AUTOSAR XML (schema 4-0-3)
standard types defined: Boolean, UInt16
package /AUTOSAR_Platform/DataConstrs
  range DC_Boolean: raw 0..1
  range DC_UInt16: raw 0..65535
package /PATAC/MSM/ComponentTypes
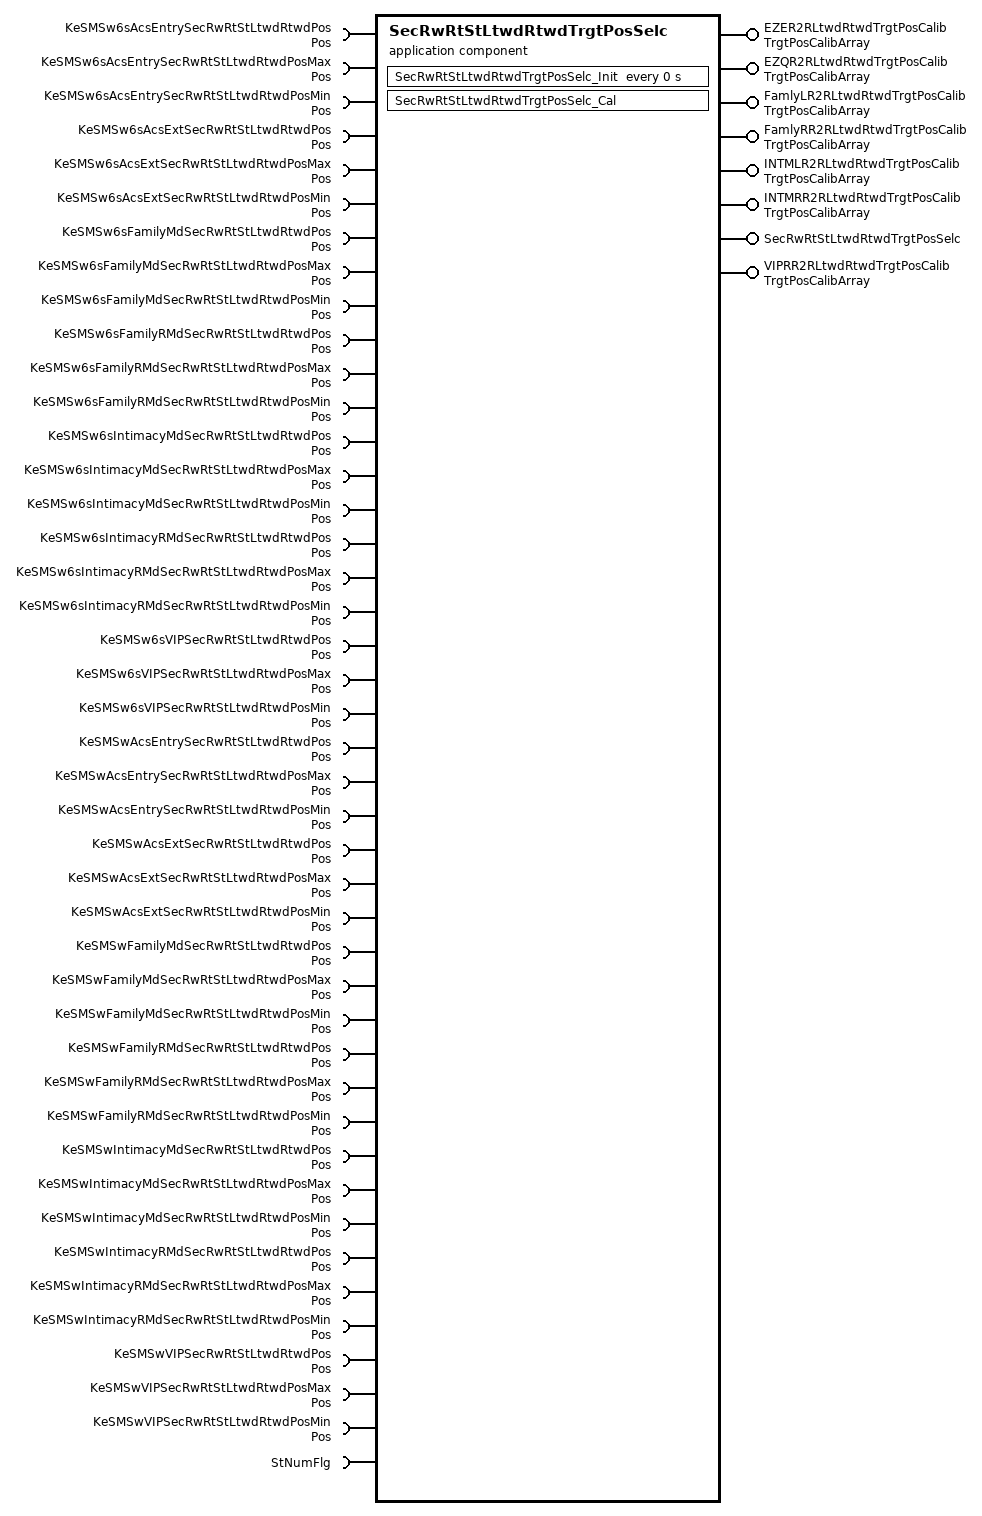
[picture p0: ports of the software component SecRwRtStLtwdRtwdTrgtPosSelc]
  application sw component type SecRwRtStLtwdRtwdTrgtPosSelc
    8 x provide port:
      EZER2RLtwdRtwdTrgtPosCalib: nonqueued-sender-com-spec{data-element=TrgtPosArray, init-value=[4095, 4095, 4095]}, provided-interface=TrgtPosCalibArray
      EZQR2RLtwdRtwdTrgtPosCalib: nonqueued-sender-com-spec{data-element=TrgtPosArray, init-value=[4095, 4095, 4095]}, provided-interface=TrgtPosCalibArray
      FamlyLR2RLtwdRtwdTrgtPosCalib: nonqueued-sender-com-spec{data-element=TrgtPosArray, init-value=[4095, 4095, 4095]}, provided-interface=TrgtPosCalibArray
      FamlyRR2RLtwdRtwdTrgtPosCalib: nonqueued-sender-com-spec{data-element=TrgtPosArray, init-value=[4095, 4095, 4095]}, provided-interface=TrgtPosCalibArray
      INTMLR2RLtwdRtwdTrgtPosCalib: nonqueued-sender-com-spec{data-element=TrgtPosArray, init-value=[4095, 4095, 4095]}, provided-interface=TrgtPosCalibArray
      INTMRR2RLtwdRtwdTrgtPosCalib: nonqueued-sender-com-spec{data-element=TrgtPosArray, init-value=[4095, 4095, 4095]}, provided-interface=TrgtPosCalibArray
      SecRwRtStLtwdRtwdTrgtPosSelc: server-com-spec{operation=Cal, queue-length=1}, provided-interface=SecRwRtStLtwdRtwdTrgtPosSelc
      VIPRR2RLtwdRtwdTrgtPosCalib: nonqueued-sender-com-spec{data-element=TrgtPosArray, init-value=[4095, 4095, 4095]}, provided-interface=TrgtPosCalibArray
    43 x require port:
      KeSMSw6sAcsEntrySecRwRtStLtwdRtwdPos: parameter-require-com-spec{init-value=4000, parameter=Val}, required-interface=Pos
      KeSMSw6sAcsEntrySecRwRtStLtwdRtwdPosMax: parameter-require-com-spec{init-value=4000, parameter=Val}, required-interface=Pos
      KeSMSw6sAcsEntrySecRwRtStLtwdRtwdPosMin: parameter-require-com-spec{init-value=4000, parameter=Val}, required-interface=Pos
      KeSMSw6sAcsExtSecRwRtStLtwdRtwdPos: parameter-require-com-spec{init-value=4000, parameter=Val}, required-interface=Pos
      KeSMSw6sAcsExtSecRwRtStLtwdRtwdPosMax: parameter-require-com-spec{init-value=4000, parameter=Val}, required-interface=Pos
      KeSMSw6sAcsExtSecRwRtStLtwdRtwdPosMin: parameter-require-com-spec{init-value=4000, parameter=Val}, required-interface=Pos
      KeSMSw6sFamilyMdSecRwRtStLtwdRtwdPos: parameter-require-com-spec{init-value=0, parameter=Val}, required-interface=Pos
      KeSMSw6sFamilyMdSecRwRtStLtwdRtwdPosMax: parameter-require-com-spec{init-value=0, parameter=Val}, required-interface=Pos
      KeSMSw6sFamilyMdSecRwRtStLtwdRtwdPosMin: parameter-require-com-spec{init-value=0, parameter=Val}, required-interface=Pos
      KeSMSw6sFamilyRMdSecRwRtStLtwdRtwdPos: parameter-require-com-spec{init-value=0, parameter=Val}, required-interface=Pos
      KeSMSw6sFamilyRMdSecRwRtStLtwdRtwdPosMax: parameter-require-com-spec{init-value=0, parameter=Val}, required-interface=Pos
      KeSMSw6sFamilyRMdSecRwRtStLtwdRtwdPosMin: parameter-require-com-spec{init-value=0, parameter=Val}, required-interface=Pos
      KeSMSw6sIntimacyMdSecRwRtStLtwdRtwdPos: parameter-require-com-spec{init-value=0, parameter=Val}, required-interface=Pos
      KeSMSw6sIntimacyMdSecRwRtStLtwdRtwdPosMax: parameter-require-com-spec{init-value=0, parameter=Val}, required-interface=Pos
      KeSMSw6sIntimacyMdSecRwRtStLtwdRtwdPosMin: parameter-require-com-spec{init-value=0, parameter=Val}, required-interface=Pos
      KeSMSw6sIntimacyRMdSecRwRtStLtwdRtwdPos: parameter-require-com-spec{init-value=0, parameter=Val}, required-interface=Pos
      KeSMSw6sIntimacyRMdSecRwRtStLtwdRtwdPosMax: parameter-require-com-spec{init-value=0, parameter=Val}, required-interface=Pos
      KeSMSw6sIntimacyRMdSecRwRtStLtwdRtwdPosMin: parameter-require-com-spec{init-value=0, parameter=Val}, required-interface=Pos
      KeSMSw6sVIPSecRwRtStLtwdRtwdPos: parameter-require-com-spec{init-value=0, parameter=Val}, required-interface=Pos
      KeSMSw6sVIPSecRwRtStLtwdRtwdPosMax: parameter-require-com-spec{init-value=40, parameter=Val}, required-interface=Pos
      KeSMSw6sVIPSecRwRtStLtwdRtwdPosMin: parameter-require-com-spec{init-value=0, parameter=Val}, required-interface=Pos
      KeSMSwAcsEntrySecRwRtStLtwdRtwdPos: parameter-require-com-spec{init-value=4000, parameter=Val}, required-interface=Pos
      KeSMSwAcsEntrySecRwRtStLtwdRtwdPosMax: parameter-require-com-spec{init-value=4000, parameter=Val}, required-interface=Pos
      KeSMSwAcsEntrySecRwRtStLtwdRtwdPosMin: parameter-require-com-spec{init-value=4000, parameter=Val}, required-interface=Pos
      KeSMSwAcsExtSecRwRtStLtwdRtwdPos: parameter-require-com-spec{init-value=4000, parameter=Val}, required-interface=Pos
      KeSMSwAcsExtSecRwRtStLtwdRtwdPosMax: parameter-require-com-spec{init-value=4000, parameter=Val}, required-interface=Pos
      KeSMSwAcsExtSecRwRtStLtwdRtwdPosMin: parameter-require-com-spec{init-value=4000, parameter=Val}, required-interface=Pos
      KeSMSwFamilyMdSecRwRtStLtwdRtwdPos: parameter-require-com-spec{init-value=0, parameter=Val}, required-interface=Pos
      KeSMSwFamilyMdSecRwRtStLtwdRtwdPosMax: parameter-require-com-spec{init-value=0, parameter=Val}, required-interface=Pos
      KeSMSwFamilyMdSecRwRtStLtwdRtwdPosMin: parameter-require-com-spec{init-value=0, parameter=Val}, required-interface=Pos
      KeSMSwFamilyRMdSecRwRtStLtwdRtwdPos: parameter-require-com-spec{init-value=0, parameter=Val}, required-interface=Pos
      KeSMSwFamilyRMdSecRwRtStLtwdRtwdPosMax: parameter-require-com-spec{init-value=0, parameter=Val}, required-interface=Pos
      KeSMSwFamilyRMdSecRwRtStLtwdRtwdPosMin: parameter-require-com-spec{init-value=0, parameter=Val}, required-interface=Pos
      KeSMSwIntimacyMdSecRwRtStLtwdRtwdPos: parameter-require-com-spec{init-value=0, parameter=Val}, required-interface=Pos
      KeSMSwIntimacyMdSecRwRtStLtwdRtwdPosMax: parameter-require-com-spec{init-value=0, parameter=Val}, required-interface=Pos
      KeSMSwIntimacyMdSecRwRtStLtwdRtwdPosMin: parameter-require-com-spec{init-value=0, parameter=Val}, required-interface=Pos
      KeSMSwIntimacyRMdSecRwRtStLtwdRtwdPos: parameter-require-com-spec{init-value=0, parameter=Val}, required-interface=Pos
      KeSMSwIntimacyRMdSecRwRtStLtwdRtwdPosMax: parameter-require-com-spec{init-value=0, parameter=Val}, required-interface=Pos
      KeSMSwIntimacyRMdSecRwRtStLtwdRtwdPosMin: parameter-require-com-spec{init-value=0, parameter=Val}, required-interface=Pos
      KeSMSwVIPSecRwRtStLtwdRtwdPos: parameter-require-com-spec{init-value=0, parameter=Val}, required-interface=Pos
      KeSMSwVIPSecRwRtStLtwdRtwdPosMax: parameter-require-com-spec{init-value=40, parameter=Val}, required-interface=Pos
      KeSMSwVIPSecRwRtStLtwdRtwdPosMin: parameter-require-com-spec{init-value=0, parameter=Val}, required-interface=Pos
      StNumFlg: required-interface=StNumFlg
        required-com-specs:
          data-element=Is4s, filter=data-filter-type=ALWAYS, init-value=0
          data-element=Is6s, filter=data-filter-type=ALWAYS, init-value=0
          data-element=Is6s7s, filter=data-filter-type=ALWAYS, init-value=0
          data-element=Is7s, filter=data-filter-type=ALWAYS, init-value=0
    behavior SecRwRtStLtwdRtwdTrgtPosSelc_InternalBehavior
      operation invoked event OIT_SecRwRtStLtwdRtwdTrgtPosSelc_Cal_SecRwRtStLtwdRtwdTrgtPosSelc_Cal: start-on-event=SecRwRtStLtwdRtwdTrgtPosSelc_Cal, operation=SecRwRtStLtwdRtwdTrgtPosSelc.Cal
      timing event SecRwRtStLtwdRtwdTrgtPosSelc_InitEvent: start-on-event=SecRwRtStLtwdRtwdTrgtPosSelc_Init, period=0
      runnable SecRwRtStLtwdRtwdTrgtPosSelc_Cal
        data-receive-point-by-arguments:
          4 x access:
            REC_StNumFlg_Is4s: accessed-variable=StNumFlg.Is4s
            REC_StNumFlg_Is6s: accessed-variable=StNumFlg.Is6s
            REC_StNumFlg_Is6s7s: accessed-variable=StNumFlg.Is6s7s
            REC_StNumFlg_Is7s: accessed-variable=StNumFlg.Is7s
        data-send-points:
          7 x access:
            SEND_EZER2RLtwdRtwdTrgtPosCalib_TrgtPosArray: accessed-variable=EZER2RLtwdRtwdTrgtPosCalib.TrgtPosArray
            SEND_EZQR2RLtwdRtwdTrgtPosCalib_TrgtPosArray: accessed-variable=EZQR2RLtwdRtwdTrgtPosCalib.TrgtPosArray
            SEND_FamlyLR2RLtwdRtwdTrgtPosCalib_TrgtPosArray: accessed-variable=FamlyLR2RLtwdRtwdTrgtPosCalib.TrgtPosArray
            SEND_FamlyRR2RLtwdRtwdTrgtPosCalib_TrgtPosArray: accessed-variable=FamlyRR2RLtwdRtwdTrgtPosCalib.TrgtPosArray
            SEND_INTMLR2RLtwdRtwdTrgtPosCalib_TrgtPosArray: accessed-variable=INTMLR2RLtwdRtwdTrgtPosCalib.TrgtPosArray
            SEND_INTMRR2RLtwdRtwdTrgtPosCalib_TrgtPosArray: accessed-variable=INTMRR2RLtwdRtwdTrgtPosCalib.TrgtPosArray
            SEND_VIPRR2RLtwdRtwdTrgtPosCalib_TrgtPosArray: accessed-variable=VIPRR2RLtwdRtwdTrgtPosCalib.TrgtPosArray
        42 x parameter access:
          PA_KeSMSw6sAcsEntrySecRwRtStLtwdRtwdPos_Val: accessed-parameter=KeSMSw6sAcsEntrySecRwRtStLtwdRtwdPos.Val
          PA_KeSMSw6sAcsEntrySecRwRtStLtwdRtwdPosMax_Val: accessed-parameter=KeSMSw6sAcsEntrySecRwRtStLtwdRtwdPosMax.Val
          PA_KeSMSw6sAcsEntrySecRwRtStLtwdRtwdPosMin_Val: accessed-parameter=KeSMSw6sAcsEntrySecRwRtStLtwdRtwdPosMin.Val
          PA_KeSMSw6sAcsExtSecRwRtStLtwdRtwdPos_Val: accessed-parameter=KeSMSw6sAcsExtSecRwRtStLtwdRtwdPos.Val
          PA_KeSMSw6sAcsExtSecRwRtStLtwdRtwdPosMax_Val: accessed-parameter=KeSMSw6sAcsExtSecRwRtStLtwdRtwdPosMax.Val
          PA_KeSMSw6sAcsExtSecRwRtStLtwdRtwdPosMin_Val: accessed-parameter=KeSMSw6sAcsExtSecRwRtStLtwdRtwdPosMin.Val
          PA_KeSMSw6sFamilyMdSecRwRtStLtwdRtwdPos_Val: accessed-parameter=KeSMSw6sFamilyMdSecRwRtStLtwdRtwdPos.Val
          PA_KeSMSw6sFamilyMdSecRwRtStLtwdRtwdPosMax_Val: accessed-parameter=KeSMSw6sFamilyMdSecRwRtStLtwdRtwdPosMax.Val
          PA_KeSMSw6sFamilyMdSecRwRtStLtwdRtwdPosMin_Val: accessed-parameter=KeSMSw6sFamilyMdSecRwRtStLtwdRtwdPosMin.Val
          PA_KeSMSw6sFamilyRMdSecRwRtStLtwdRtwdPos_Val: accessed-parameter=KeSMSw6sFamilyRMdSecRwRtStLtwdRtwdPos.Val
          PA_KeSMSw6sFamilyRMdSecRwRtStLtwdRtwdPosMax_Val: accessed-parameter=KeSMSw6sFamilyRMdSecRwRtStLtwdRtwdPosMax.Val
          PA_KeSMSw6sFamilyRMdSecRwRtStLtwdRtwdPosMin_Val: accessed-parameter=KeSMSw6sFamilyRMdSecRwRtStLtwdRtwdPosMin.Val
          PA_KeSMSw6sIntimacyMdSecRwRtStLtwdRtwdPos_Val: accessed-parameter=KeSMSw6sIntimacyMdSecRwRtStLtwdRtwdPos.Val
          PA_KeSMSw6sIntimacyMdSecRwRtStLtwdRtwdPosMax_Val: accessed-parameter=KeSMSw6sIntimacyMdSecRwRtStLtwdRtwdPosMax.Val
          PA_KeSMSw6sIntimacyMdSecRwRtStLtwdRtwdPosMin_Val: accessed-parameter=KeSMSw6sIntimacyMdSecRwRtStLtwdRtwdPosMin.Val
          PA_KeSMSw6sIntimacyRMdSecRwRtStLtwdRtwdPos_Val: accessed-parameter=KeSMSw6sIntimacyRMdSecRwRtStLtwdRtwdPos.Val
          PA_KeSMSw6sIntimacyRMdSecRwRtStLtwdRtwdPosMax_Val: accessed-parameter=KeSMSw6sIntimacyRMdSecRwRtStLtwdRtwdPosMax.Val
          PA_KeSMSw6sIntimacyRMdSecRwRtStLtwdRtwdPosMin_Val: accessed-parameter=KeSMSw6sIntimacyRMdSecRwRtStLtwdRtwdPosMin.Val
          PA_KeSMSw6sVIPSecRwRtStLtwdRtwdPos_Val: accessed-parameter=KeSMSw6sVIPSecRwRtStLtwdRtwdPos.Val
          PA_KeSMSw6sVIPSecRwRtStLtwdRtwdPosMax_Val: accessed-parameter=KeSMSw6sVIPSecRwRtStLtwdRtwdPosMax.Val
          PA_KeSMSw6sVIPSecRwRtStLtwdRtwdPosMin_Val: accessed-parameter=KeSMSw6sVIPSecRwRtStLtwdRtwdPosMin.Val
          PA_KeSMSwAcsEntrySecRwRtStLtwdRtwdPos_Val: accessed-parameter=KeSMSwAcsEntrySecRwRtStLtwdRtwdPos.Val
          PA_KeSMSwAcsEntrySecRwRtStLtwdRtwdPosMax_Val: accessed-parameter=KeSMSwAcsEntrySecRwRtStLtwdRtwdPosMax.Val
          PA_KeSMSwAcsEntrySecRwRtStLtwdRtwdPosMin_Val: accessed-parameter=KeSMSwAcsEntrySecRwRtStLtwdRtwdPosMin.Val
          PA_KeSMSwAcsExtSecRwRtStLtwdRtwdPos_Val: accessed-parameter=KeSMSwAcsExtSecRwRtStLtwdRtwdPos.Val
          PA_KeSMSwAcsExtSecRwRtStLtwdRtwdPosMax_Val: accessed-parameter=KeSMSwAcsExtSecRwRtStLtwdRtwdPosMax.Val
          PA_KeSMSwAcsExtSecRwRtStLtwdRtwdPosMin_Val: accessed-parameter=KeSMSwAcsExtSecRwRtStLtwdRtwdPosMin.Val
          PA_KeSMSwFamilyMdSecRwRtStLtwdRtwdPos_Val: accessed-parameter=KeSMSwFamilyMdSecRwRtStLtwdRtwdPos.Val
          PA_KeSMSwFamilyMdSecRwRtStLtwdRtwdPosMax_Val: accessed-parameter=KeSMSwFamilyMdSecRwRtStLtwdRtwdPosMax.Val
          PA_KeSMSwFamilyMdSecRwRtStLtwdRtwdPosMin_Val: accessed-parameter=KeSMSwFamilyMdSecRwRtStLtwdRtwdPosMin.Val
          PA_KeSMSwFamilyRMdSecRwRtStLtwdRtwdPos_Val: accessed-parameter=KeSMSwFamilyRMdSecRwRtStLtwdRtwdPos.Val
          PA_KeSMSwFamilyRMdSecRwRtStLtwdRtwdPosMax_Val: accessed-parameter=KeSMSwFamilyRMdSecRwRtStLtwdRtwdPosMax.Val
          PA_KeSMSwFamilyRMdSecRwRtStLtwdRtwdPosMin_Val: accessed-parameter=KeSMSwFamilyRMdSecRwRtStLtwdRtwdPosMin.Val
          PA_KeSMSwIntimacyMdSecRwRtStLtwdRtwdPos_Val: accessed-parameter=KeSMSwIntimacyMdSecRwRtStLtwdRtwdPos.Val
          PA_KeSMSwIntimacyMdSecRwRtStLtwdRtwdPosMax_Val: accessed-parameter=KeSMSwIntimacyMdSecRwRtStLtwdRtwdPosMax.Val
          PA_KeSMSwIntimacyMdSecRwRtStLtwdRtwdPosMin_Val: accessed-parameter=KeSMSwIntimacyMdSecRwRtStLtwdRtwdPosMin.Val
          PA_KeSMSwIntimacyRMdSecRwRtStLtwdRtwdPos_Val: accessed-parameter=KeSMSwIntimacyRMdSecRwRtStLtwdRtwdPos.Val
          PA_KeSMSwIntimacyRMdSecRwRtStLtwdRtwdPosMax_Val: accessed-parameter=KeSMSwIntimacyRMdSecRwRtStLtwdRtwdPosMax.Val
          PA_KeSMSwIntimacyRMdSecRwRtStLtwdRtwdPosMin_Val: accessed-parameter=KeSMSwIntimacyRMdSecRwRtStLtwdRtwdPosMin.Val
          PA_KeSMSwVIPSecRwRtStLtwdRtwdPos_Val: accessed-parameter=KeSMSwVIPSecRwRtStLtwdRtwdPos.Val
          PA_KeSMSwVIPSecRwRtStLtwdRtwdPosMax_Val: accessed-parameter=KeSMSwVIPSecRwRtStLtwdRtwdPosMax.Val
          PA_KeSMSwVIPSecRwRtStLtwdRtwdPosMin_Val: accessed-parameter=KeSMSwVIPSecRwRtStLtwdRtwdPosMin.Val
      runnable SecRwRtStLtwdRtwdTrgtPosSelc_Init
        42 x parameter access:
          PA_KeSMSw6sAcsEntrySecRwRtStLtwdRtwdPos_Val: accessed-parameter=KeSMSw6sAcsEntrySecRwRtStLtwdRtwdPos.Val
          PA_KeSMSw6sAcsEntrySecRwRtStLtwdRtwdPosMax_Val: accessed-parameter=KeSMSw6sAcsEntrySecRwRtStLtwdRtwdPosMax.Val
          PA_KeSMSw6sAcsEntrySecRwRtStLtwdRtwdPosMin_Val: accessed-parameter=KeSMSw6sAcsEntrySecRwRtStLtwdRtwdPosMin.Val
          PA_KeSMSw6sAcsExtSecRwRtStLtwdRtwdPos_Val: accessed-parameter=KeSMSw6sAcsExtSecRwRtStLtwdRtwdPos.Val
          PA_KeSMSw6sAcsExtSecRwRtStLtwdRtwdPosMax_Val: accessed-parameter=KeSMSw6sAcsExtSecRwRtStLtwdRtwdPosMax.Val
          PA_KeSMSw6sAcsExtSecRwRtStLtwdRtwdPosMin_Val: accessed-parameter=KeSMSw6sAcsExtSecRwRtStLtwdRtwdPosMin.Val
          PA_KeSMSw6sFamilyMdSecRwRtStLtwdRtwdPos_Val: accessed-parameter=KeSMSw6sFamilyMdSecRwRtStLtwdRtwdPos.Val
          PA_KeSMSw6sFamilyMdSecRwRtStLtwdRtwdPosMax_Val: accessed-parameter=KeSMSw6sFamilyMdSecRwRtStLtwdRtwdPosMax.Val
          PA_KeSMSw6sFamilyMdSecRwRtStLtwdRtwdPosMin_Val: accessed-parameter=KeSMSw6sFamilyMdSecRwRtStLtwdRtwdPosMin.Val
          PA_KeSMSw6sFamilyRMdSecRwRtStLtwdRtwdPos_Val: accessed-parameter=KeSMSw6sFamilyRMdSecRwRtStLtwdRtwdPos.Val
          PA_KeSMSw6sFamilyRMdSecRwRtStLtwdRtwdPosMax_Val: accessed-parameter=KeSMSw6sFamilyRMdSecRwRtStLtwdRtwdPosMax.Val
          PA_KeSMSw6sFamilyRMdSecRwRtStLtwdRtwdPosMin_Val: accessed-parameter=KeSMSw6sFamilyRMdSecRwRtStLtwdRtwdPosMin.Val
          PA_KeSMSw6sIntimacyMdSecRwRtStLtwdRtwdPos_Val: accessed-parameter=KeSMSw6sIntimacyMdSecRwRtStLtwdRtwdPos.Val
          PA_KeSMSw6sIntimacyMdSecRwRtStLtwdRtwdPosMax_Val: accessed-parameter=KeSMSw6sIntimacyMdSecRwRtStLtwdRtwdPosMax.Val
          PA_KeSMSw6sIntimacyMdSecRwRtStLtwdRtwdPosMin_Val: accessed-parameter=KeSMSw6sIntimacyMdSecRwRtStLtwdRtwdPosMin.Val
          PA_KeSMSw6sIntimacyRMdSecRwRtStLtwdRtwdPos_Val: accessed-parameter=KeSMSw6sIntimacyRMdSecRwRtStLtwdRtwdPos.Val
          PA_KeSMSw6sIntimacyRMdSecRwRtStLtwdRtwdPosMax_Val: accessed-parameter=KeSMSw6sIntimacyRMdSecRwRtStLtwdRtwdPosMax.Val
          PA_KeSMSw6sIntimacyRMdSecRwRtStLtwdRtwdPosMin_Val: accessed-parameter=KeSMSw6sIntimacyRMdSecRwRtStLtwdRtwdPosMin.Val
          PA_KeSMSw6sVIPSecRwRtStLtwdRtwdPos_Val: accessed-parameter=KeSMSw6sVIPSecRwRtStLtwdRtwdPos.Val
          PA_KeSMSw6sVIPSecRwRtStLtwdRtwdPosMax_Val: accessed-parameter=KeSMSw6sVIPSecRwRtStLtwdRtwdPosMax.Val
          PA_KeSMSw6sVIPSecRwRtStLtwdRtwdPosMin_Val: accessed-parameter=KeSMSw6sVIPSecRwRtStLtwdRtwdPosMin.Val
          PA_KeSMSwAcsEntrySecRwRtStLtwdRtwdPos_Val: accessed-parameter=KeSMSwAcsEntrySecRwRtStLtwdRtwdPos.Val
          PA_KeSMSwAcsEntrySecRwRtStLtwdRtwdPosMax_Val: accessed-parameter=KeSMSwAcsEntrySecRwRtStLtwdRtwdPosMax.Val
          PA_KeSMSwAcsEntrySecRwRtStLtwdRtwdPosMin_Val: accessed-parameter=KeSMSwAcsEntrySecRwRtStLtwdRtwdPosMin.Val
          PA_KeSMSwAcsExtSecRwRtStLtwdRtwdPos_Val: accessed-parameter=KeSMSwAcsExtSecRwRtStLtwdRtwdPos.Val
          PA_KeSMSwAcsExtSecRwRtStLtwdRtwdPosMax_Val: accessed-parameter=KeSMSwAcsExtSecRwRtStLtwdRtwdPosMax.Val
          PA_KeSMSwAcsExtSecRwRtStLtwdRtwdPosMin_Val: accessed-parameter=KeSMSwAcsExtSecRwRtStLtwdRtwdPosMin.Val
          PA_KeSMSwFamilyMdSecRwRtStLtwdRtwdPos_Val: accessed-parameter=KeSMSwFamilyMdSecRwRtStLtwdRtwdPos.Val
          PA_KeSMSwFamilyMdSecRwRtStLtwdRtwdPosMax_Val: accessed-parameter=KeSMSwFamilyMdSecRwRtStLtwdRtwdPosMax.Val
          PA_KeSMSwFamilyMdSecRwRtStLtwdRtwdPosMin_Val: accessed-parameter=KeSMSwFamilyMdSecRwRtStLtwdRtwdPosMin.Val
          PA_KeSMSwFamilyRMdSecRwRtStLtwdRtwdPos_Val: accessed-parameter=KeSMSwFamilyRMdSecRwRtStLtwdRtwdPos.Val
          PA_KeSMSwFamilyRMdSecRwRtStLtwdRtwdPosMax_Val: accessed-parameter=KeSMSwFamilyRMdSecRwRtStLtwdRtwdPosMax.Val
          PA_KeSMSwFamilyRMdSecRwRtStLtwdRtwdPosMin_Val: accessed-parameter=KeSMSwFamilyRMdSecRwRtStLtwdRtwdPosMin.Val
          PA_KeSMSwIntimacyMdSecRwRtStLtwdRtwdPos_Val: accessed-parameter=KeSMSwIntimacyMdSecRwRtStLtwdRtwdPos.Val
          PA_KeSMSwIntimacyMdSecRwRtStLtwdRtwdPosMax_Val: accessed-parameter=KeSMSwIntimacyMdSecRwRtStLtwdRtwdPosMax.Val
          PA_KeSMSwIntimacyMdSecRwRtStLtwdRtwdPosMin_Val: accessed-parameter=KeSMSwIntimacyMdSecRwRtStLtwdRtwdPosMin.Val
          PA_KeSMSwIntimacyRMdSecRwRtStLtwdRtwdPos_Val: accessed-parameter=KeSMSwIntimacyRMdSecRwRtStLtwdRtwdPos.Val
          PA_KeSMSwIntimacyRMdSecRwRtStLtwdRtwdPosMax_Val: accessed-parameter=KeSMSwIntimacyRMdSecRwRtStLtwdRtwdPosMax.Val
          PA_KeSMSwIntimacyRMdSecRwRtStLtwdRtwdPosMin_Val: accessed-parameter=KeSMSwIntimacyRMdSecRwRtStLtwdRtwdPosMin.Val
          PA_KeSMSwVIPSecRwRtStLtwdRtwdPos_Val: accessed-parameter=KeSMSwVIPSecRwRtStLtwdRtwdPos.Val
          PA_KeSMSwVIPSecRwRtStLtwdRtwdPosMax_Val: accessed-parameter=KeSMSwVIPSecRwRtStLtwdRtwdPosMax.Val
          PA_KeSMSwVIPSecRwRtStLtwdRtwdPosMin_Val: accessed-parameter=KeSMSwVIPSecRwRtStLtwdRtwdPosMin.Val
  swc implementation SecRwRtStLtwdRtwdTrgtPosSelc_Implementation: behavior=SecRwRtStLtwdRtwdTrgtPosSelc_InternalBehavior
    code-descriptors:
      code Default: artifact-descriptors=autosar-engineering-object={short-label=Default, category=SWSRC}
package /PATAC/MSM/ModeAdjust/CalPortInterface
  parameter interface Pos
    parameter data prototype Val: sw-calibration-access=READ-WRITE, type=UInt16
package /PATAC/MSM/ModeAdjust/DataType
  impl type TrgtPosCalibArray: category=ARRAY, sw-calibration-access=READ-ONLY, type-emitter=RTE  # 0:pos 1:max 2:min
    element Element: array-size=3, array-size-semantics=FIXED-SIZE, implementation-data-type=UInt16, invalid-value=0
package /PATAC/MSM/ModeAdjust/PortInterface
  client server interface SecRwRtStLtwdRtwdTrgtPosSelc
    operation Cal
  sender receiver interface StNumFlg
    4 x data, all with type=Boolean:
      Is4s
      Is6s
      Is6s7s
      Is7s
    invalidation-policys:
      data-element=Is7s, handle-invalid=DONT-INVALIDATE
      data-element=Is6s, handle-invalid=DONT-INVALIDATE
      data-element=Is4s, handle-invalid=DONT-INVALIDATE
      data-element=Is6s7s, handle-invalid=DONT-INVALIDATE
  sender receiver interface TrgtPosCalibArray: invalidation-policy{data-element=TrgtPosArray, handle-invalid=DONT-INVALIDATE}
    data TrgtPosArray: type=TrgtPosCalibArray  # 0:Pos 1:Max 2:Min
